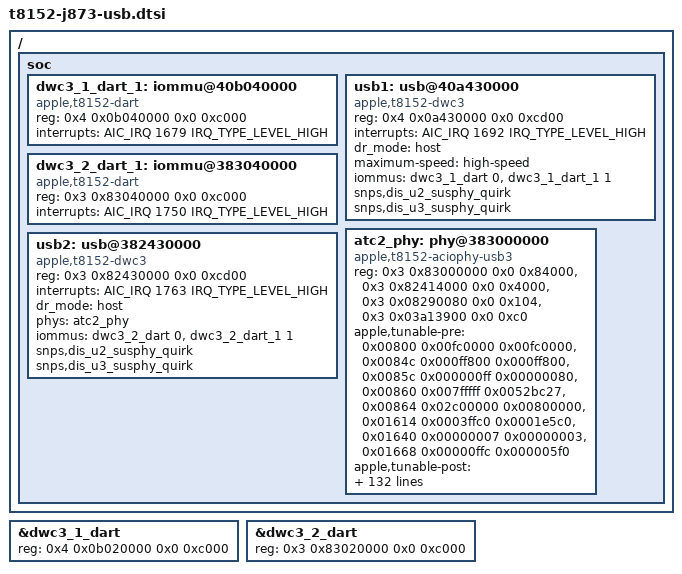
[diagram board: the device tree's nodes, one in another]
// SPDX-License-Identifier: GPL-2.0+ OR MIT
/*
 * J873g USB host bring-up: usb-drd1 (back-left port, USB2) and usb-drd2
 * (front ports via the on-board hub, USB2 and USB3).
 * The loader powers the controllers and sets up the USB2 side of their ATC
 * PHYs for host mode before Linux starts (there is no T8152 USB power-domain,
 * USB2 PHY or Type-C support yet).
 * The controllers are described by their DWC3 core region, as hosts behind
 * their two DARTs (apple,t8152-dwc3); their PHY reset and power domain, and on
 * the Type-C port the role switch, exist but are left to the loader.
 * usb-drd2's hub is wired to ATC2's PHY without a Type-C mux, so Linux brings
 * that PHY up in USB3 mode (atc2_phy).
 * Resources are from the 26A434 ADT: dart-usb1/2, usb-drd1/2, atc-phy2.
 *
 * dart-usb1 and dart-usb2 each have two DART instances (ADT reg[0] and
 * reg[1], 0xc000 each, sharing one interrupt). t8152-peripherals.dtsi lists
 * both windows on one node (dwc3_1_dart, dwc3_2_dart), but the DART driver
 * drives one instance per node and the binding reads a second reg entry as
 * DAPF or auxiliary registers. Keep instance 0 on the shared node, with its
 * own window only, and describe instance 1 as a node of its own.
 */

&dwc3_1_dart {
	reg = <0x4 0x0b020000 0x0 0xc000>;
	status = "okay";
};

&dwc3_2_dart {
	reg = <0x3 0x83020000 0x0 0xc000>;
	status = "okay";
};

/ {
	soc {
		dwc3_1_dart_1: iommu@40b040000 {
			compatible = "apple,t8152-dart", "apple,t8110-dart";
			reg = <0x4 0x0b040000 0x0 0xc000>;
			interrupts = <AIC_IRQ 1679 IRQ_TYPE_LEVEL_HIGH>;
			#iommu-cells = <1>;
		};

		usb1: usb@40a430000 {
			compatible = "apple,t8152-dwc3";
			reg = <0x4 0x0a430000 0x0 0xcd00>;
			interrupts = <AIC_IRQ 1692 IRQ_TYPE_LEVEL_HIGH>;
			dr_mode = "host";
			maximum-speed = "high-speed";
			iommus = <&dwc3_1_dart 0>, <&dwc3_1_dart_1 1>;
			snps,dis_u2_susphy_quirk;
			snps,dis_u3_susphy_quirk;
		};

		dwc3_2_dart_1: iommu@383040000 {
			compatible = "apple,t8152-dart", "apple,t8110-dart";
			reg = <0x3 0x83040000 0x0 0xc000>;
			interrupts = <AIC_IRQ 1750 IRQ_TYPE_LEVEL_HIGH>;
			#iommu-cells = <1>;
		};

		/*
		 * ADT atc-phy2 in USB3 mode for usb-drd2: the hub is wired to the
		 * PHY directly. PS: the ATC's DP_0, DP_1 and USB_AON power states
		 * (+0, +0x20, +0x100), PSD: its common domain (clock-gates 57).
		 * The tunables are the atc-phy2 tunable_* groups of the 26A434 ADT
		 * that macOS applies for USB3 on lane 0, in its order.
		 */
		atc2_phy: phy@383000000 {
			compatible = "apple,t8152-aciophy-usb3";
			reg = <0x3 0x83000000 0x0 0x84000>,
			      <0x3 0x82414000 0x0 0x4000>,
			      <0x3 0x08290080 0x0 0x104>,
			      <0x3 0x03a13900 0x0 0xc0>;
			reg-names = "atc", "pipehandler", "atc-ps", "atc-psd";
			#phy-cells = <0>;
			apple,tunable-pre =
				/* ACIOPHY_CMN_DFLT */
				<0x00800 0x00fc0000 0x00fc0000>,
				<0x0084c 0x000ff800 0x000ff800>,
				<0x0085c 0x000000ff 0x00000080>,
				<0x00860 0x007fffff 0x0052bc27>,
				<0x00864 0x02c00000 0x00800000>,
				/* CIOPLL_CORE_DFLT */
				<0x01614 0x0003ffc0 0x0001e5c0>,
				<0x01640 0x00000007 0x00000003>,
				<0x01668 0x00000ffc 0x000005f0>;
			apple,tunable-post =
				/* ATC_FABRIC */
				<0x6c004 0x003f003f 0x00200020>,
				<0x6c00c 0x000000f1 0x000000a1>,
				<0x6c010 0x0000801f 0x00000004>,
				<0x6c018 0x003f003f 0x00200020>,
				<0x6c020 0x000000f1 0x000000a1>,
				<0x6c024 0x0000801f 0x00000004>,
				<0x6c02c 0x007f007f 0x00410041>,
				<0x6c034 0x000000f1 0x00000071>,
				<0x6c038 0x0000801f 0x00000004>,
				<0x6c040 0x0000001f 0x00000010>,
				<0x6c048 0x0000801f 0x00000004>,
				<0x6c050 0x007f007f 0x00450045>,
				<0x6c058 0x000000f1 0x00000051>,
				<0x6c05c 0x0000801f 0x00000004>,
				<0x6c064 0x0000003f 0x00000020>,
				<0x6c06c 0x0000801f 0x00000004>,
				<0x6c074 0x00000001 0x00000001>,
				<0x6c078 0x0000801f 0x00000004>,
				<0x6c080 0x001f001f 0x00100010>,
				<0x6c084 0x000000f1 0x00000011>,
				<0x6c088 0x00000001 0x00000001>,
				<0x6c08c 0x00000001 0x00000001>,
				<0x6c090 0x0000801f 0x00000004>,
				<0x6c098 0x001f001f 0x00100010>,
				<0x6c09c 0x000000f1 0x00000011>,
				<0x6c0a0 0x0000801f 0x00000004>,
				<0x6c0a8 0x000000ff 0x000000a0>,
				<0x6c0ac 0x0000801f 0x00000004>,
				<0x6c0b4 0x0000003f 0x00000020>,
				<0x6c0bc 0x0000801f 0x00000004>,
				<0x6c0c4 0x0000003f 0x00000020>,
				<0x6c0cc 0x0000801f 0x00000004>,
				<0x6c0d4 0x0000000f 0x00000008>,
				<0x6c0d8 0x0000801f 0x00000004>,
				<0x6c0e0 0x001f001f 0x00180018>,
				<0x6c0e4 0x0000801f 0x00000004>,
				<0x6c0ec 0x001f001f 0x00180018>,
				<0x6c0f0 0x0000801f 0x00000004>,
				<0x6c0f8 0x001f001f 0x00180018>,
				<0x6c0fc 0x0000801f 0x00000004>,
				<0x6c104 0x001f001f 0x00180018>,
				<0x6c108 0x0000801f 0x00000004>,
				<0x6c110 0x00000001 0x00000001>,
				<0x6c114 0x0000801f 0x00000004>,
				<0x6c11c 0x0000801f 0x00000004>,
				<0x6c124 0x0000801f 0x00000004>,
				<0x6c12c 0x0000801f 0x00000004>,
				<0x6c134 0x0000801f 0x00000004>,
				<0x6c13c 0xffffffff 0x01010101>,
				<0x6c140 0x0000801f 0x00000004>,
				<0x6c148 0x0000801f 0x00000004>,
				<0x6c150 0xffffffff 0x01010101>,
				<0x6c154 0x0000ffff 0x00000101>,
				<0x6c158 0x0000801f 0x00000004>,
				<0x6c160 0x0000801f 0x00000004>,
				<0x6c168 0x0000801f 0x00000004>,
				<0x6c170 0x0000801f 0x00000004>,
				<0x6c178 0x0000801f 0x00000004>,
				<0x6c180 0xffffffff 0x01010101>,
				<0x6c184 0x0000801f 0x00000004>,
				<0x6c18c 0x0000801f 0x00000004>,
				<0x6c194 0x0000801f 0x00000004>,
				/* DPPLL_CORE_DFLT */
				<0x01040 0x0000000c 0x00000008>,
				<0x01060 0x0001c000 0x0000c000>,
				<0x01098 0x00000f00 0x00000800>,
				<0x0109c 0x000fe000 0x000fe000>,
				<0x01108 0x07c00000 0x04000000>,
				<0x0110c 0x0000007c 0x00000010>,
				/* DPPLL_TOP_DFLT */
				<0x00e8c 0x0000007f 0x0000003c>,
				<0x00e9c 0x0000007f 0x00000032>,
				<0x00eac 0x0000007f 0x00000032>,
				<0x00ebc 0x0000007f 0x0000005a>,
				/* CIOPLL_TOP_DFLT */
				<0x01488 0x000001ff 0x00000128>,
				<0x01494 0x00000100 0x00000100>,
				/* ACIOPHY_USBC0_DFLT */
				<0x15c04 0x0f000000 0x00000000>,
				<0x15c0c 0x0007c000 0x00020000>,
				/* ACIOPHY_USBC0_USB */
				<0x15c50 0x60000000 0x00000000>,
				/* LN0_ARBITER_REGS_DFLT */
				<0x082d8 0xf0000000 0x70000000>,
				<0x082dc 0x0000000f 0x00000007>,
				/* LN0_RX_TOP_REGS_DFLT */
				<0x08cf4 0x00000020 0x00000020>,
				/* LN0_RX_DFE_REGS_DFLT */
				<0x077c4 0x0003ff00 0x0000fa00>,
				/* LN0_SMGR_REGS_DFLT */
				<0x07dbc 0x00000078 0x00000030>,
				<0x07dd8 0x000003f0 0x00000000>,
				<0x07de8 0x00000003 0x00000003>,
				<0x07dec 0x00000002 0x00000002>,
				/* LN0_RXAEQ_TOP_REGS_DFLT */
				<0x07a00 0x000000f0 0x00000010>,
				<0x07a08 0x00000fff 0x00000001>,
				<0x07a28 0x0ff00000 0x0cf00000>,
				<0x07a40 0x07ffffff 0x028154a5>,
				<0x07a7c 0x20000000 0x00000000>,
				<0x07a80 0x0000001f 0x00000002>,
				<0x07b98 0x3f00003f 0x31000014>,
				<0x07b9c 0x0003ffff 0x0000ef4b>,
				<0x07ba8 0x0fc1f800 0x05005000>,
				<0x07bac 0x07ffffe0 0x013f0e40>,
				<0x07bbc 0x000001c7 0x00000145>,
				<0x07bc8 0x000007f8 0x00000018>,
				/* LN0_RX_SHM_REGS_DFLT */
				<0x08728 0x0000010f 0x0000010f>,
				<0x0878c 0xfc000000 0xfc000000>,
				<0x08790 0x00000001 0x00000001>,
				<0x087b4 0x0e018000 0x06008000>,
				<0x08708 0x40000000 0x40000000>,
				/* LN0_TXSEQ_REGS_DFLT */
				<0x04c80 0x3f800000 0x00000000>,
				<0x04c88 0x001fffff 0x00000000>,
				/* LN0_TX_SHM_AHB_DFLT */
				<0x04fd4 0x03800000 0x02800000>,
				/* LN0_TX_TXSPL_CM_DFLT */
				<0x04e20 0x00fff000 0x00723000>,
				/* LN0_ASDC_TXSPL_CM_DFLT */
				<0x08980 0x00fff000 0x00723000>,
				/* LN0_DIV40_REGS_DFLT */
				<0x085e4 0x00000004 0x00000000>,
				/* LN0_RX_PCTRL_REGS_DFLT */
				<0x08628 0x00000ff0 0x00000660>,
				<0x0862c 0x00000ff0 0x00000ea0>,
				/* LN0_CTLE_EQ_REGS_DFLT */
				<0x08000 0x0000000a 0x00000000>,
				<0x08014 0x000003ff 0x00000042>,
				/* L0_RXCALACC_HALFUI_DFLT */
				<0x07304 0x0000000f 0x00000006>,
				<0x07334 0x01ffffff 0x001004ea>,
				/* L0_RXCALACC_EDSKEW_DFLT */
				<0x07284 0x0000000f 0x00000006>,
				<0x072cc 0x0003ffff 0x000004ea>,
				/* LN0_TXSPL_TXDCC_DFLT */
				<0x04d84 0x001c0000 0x00000000>,
				/* LN0_SMGR_REGS_USB */
				<0x07d88 0x000000f0 0x00000030>,
				<0x07da8 0xff000000 0x44000000>,
				<0x07dd8 0x00003000 0x00003000>,
				/* LN0_DETECTOR_REGS_USB */
				<0x0848c 0x00008000 0x00000000>,
				/* LN0_DIV40_REGS_USB */
				<0x08594 0x00000001 0x00000001>,
				<0x085b0 0x0000ffff 0x00001010>,
				<0x085b8 0x0000ffff 0x00001010>,
				<0x085cc 0x68100000 0x00000000>,
				<0x085d0 0x68100000 0x00000000>,
				/* LN0_CTLE_EQ_REGS_USB */
				<0x07fdc 0x000001ff 0x000000b4>,
				<0x07fe0 0x000001ff 0x000000aa>,
				/* LN0_RXAEQ_TOP_REGS_USB */
				<0x07a1c 0x00000ff8 0x00000578>,
				<0x07a2c 0x0003ffff 0x000154b4>,
				<0x07bb8 0x00007000 0x00000000>,
				/* LN0_TXSEQ_REGS_USB */
				<0x04ca0 0x00000002 0x00000000>;
		};

		/* usb-drd2: on-board VL822 hub behind the two front USB-C ports. */
		usb2: usb@382430000 {
			compatible = "apple,t8152-dwc3";
			reg = <0x3 0x82430000 0x0 0xcd00>;
			interrupts = <AIC_IRQ 1763 IRQ_TYPE_LEVEL_HIGH>;
			dr_mode = "host";
			phys = <&atc2_phy>;
			phy-names = "usb3-phy";
			iommus = <&dwc3_2_dart 0>, <&dwc3_2_dart_1 1>;
			snps,dis_u2_susphy_quirk;
			snps,dis_u3_susphy_quirk;
		};
	};
};
